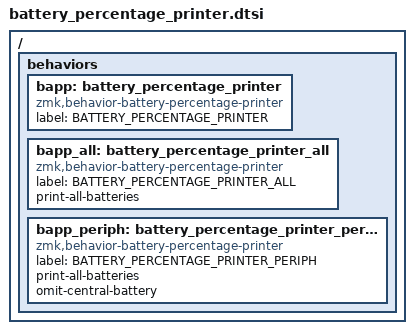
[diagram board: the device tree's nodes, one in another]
/ {
    behaviors {
        /omit-if-no-ref/ bapp: battery_percentage_printer {
                compatible = "zmk,behavior-battery-percentage-printer";
                label = "BATTERY_PERCENTAGE_PRINTER";
                #binding-cells = <0>;
        };

        /omit-if-no-ref/ bapp_all: battery_percentage_printer_all {
                compatible = "zmk,behavior-battery-percentage-printer";
                label = "BATTERY_PERCENTAGE_PRINTER_ALL";
                print-all-batteries;
                #binding-cells = <0>;
        };

        /omit-if-no-ref/ bapp_periph: battery_percentage_printer_periph {
                compatible = "zmk,behavior-battery-percentage-printer";
                label = "BATTERY_PERCENTAGE_PRINTER_PERIPH";
                print-all-batteries;
                omit-central-battery;
                #binding-cells = <0>;
        };
    };
};
